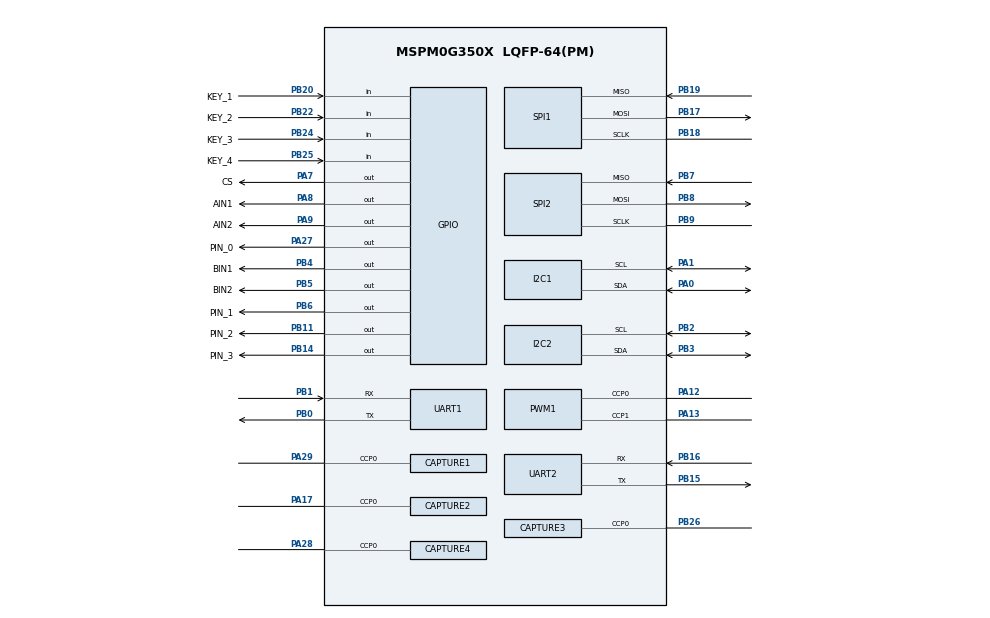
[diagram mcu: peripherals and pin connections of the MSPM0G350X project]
/**
 * @cliArgs --device "MSPM0G350X" --part "Default" --package "LQFP-64(PM)" --product "mspm0_sdk@2.10.00.04"
 * @versions {"tool":"1.26.2+4477"}
 */

/**
 * Import the modules used in this configuration.
 */
const CAPTURE  = scripting.addModule("/ti/driverlib/CAPTURE", {}, false);
const CAPTURE1 = CAPTURE.addInstance();
const CAPTURE2 = CAPTURE.addInstance();
const CAPTURE3 = CAPTURE.addInstance();
const CAPTURE4 = CAPTURE.addInstance();
const DMA      = scripting.addModule("/ti/driverlib/DMA");
const GPIO     = scripting.addModule("/ti/driverlib/GPIO", {}, false);
const GPIO1    = GPIO.addInstance();
const GPIO2    = GPIO.addInstance();
const GPIO3    = GPIO.addInstance();
const GPIO4    = GPIO.addInstance();
const GPIO5    = GPIO.addInstance();
const GPIO6    = GPIO.addInstance();
const GPIO7    = GPIO.addInstance();
const I2C      = scripting.addModule("/ti/driverlib/I2C", {}, false);
const I2C1     = I2C.addInstance();
const I2C2     = I2C.addInstance();
const PWM      = scripting.addModule("/ti/driverlib/PWM", {}, false);
const PWM1     = PWM.addInstance();
const SPI      = scripting.addModule("/ti/driverlib/SPI", {}, false);
const SPI1     = SPI.addInstance();
const SPI2     = SPI.addInstance();
const SYSCTL   = scripting.addModule("/ti/driverlib/SYSCTL");
const TIMER    = scripting.addModule("/ti/driverlib/TIMER", {}, false);
const TIMER1   = TIMER.addInstance();
const UART     = scripting.addModule("/ti/driverlib/UART", {}, false);
const UART1    = UART.addInstance();
const UART2    = UART.addInstance();
const UART3    = UART.addInstance();

/**
 * Write custom configuration values to the imported modules.
 */
const divider9       = system.clockTree["UDIV"];
divider9.divideValue = 2;

const mux4       = system.clockTree["EXHFMUX"];
mux4.inputSelect = "EXHFMUX_XTAL";

const mux8       = system.clockTree["HSCLKMUX"];
mux8.inputSelect = "HSCLKMUX_SYSPLL2X";

const mux12       = system.clockTree["SYSPLLMUX"];
mux12.inputSelect = "zSYSPLLMUX_HFCLK";

const pinFunction4        = system.clockTree["HFXT"];
pinFunction4.enable       = true;
pinFunction4.inputFreq    = 40;
pinFunction4.HFXTStartup  = 20;
pinFunction4.HFCLKMonitor = true;

CAPTURE1.$name                              = "E1A";
CAPTURE1.timerClkPrescale                   = 10;
CAPTURE1.interrupts                         = ["CC0_DN","CC0_UP","ZERO"];
CAPTURE1.captEdgeDetection                  = "EDGE";
CAPTURE1.timerPeriod                        = "20ms";
CAPTURE1.timerClkDiv                        = 8;
CAPTURE1.peripheral.$assign                 = "TIMG8";
CAPTURE1.peripheral.ccp0Pin.$assign         = "PA29";
CAPTURE1.ccp0PinConfig.$name                = "ti_driverlib_gpio_GPIOPinGeneric0";
CAPTURE1.ccp0PinConfig.hideOutputInversion  = scripting.forceWrite(false);
CAPTURE1.ccp0PinConfig.onlyInternalResistor = scripting.forceWrite(false);
CAPTURE1.ccp0PinConfig.passedPeripheralType = scripting.forceWrite("Digital");

const Board = scripting.addModule("/ti/driverlib/Board", {}, false);

CAPTURE2.$name                              = "E1B";
CAPTURE2.timerClkDiv                        = 8;
CAPTURE2.timerClkPrescale                   = 10;
CAPTURE2.interrupts                         = ["CC0_DN","CC0_UP","ZERO"];
CAPTURE2.captEdgeDetection                  = "EDGE";
CAPTURE2.timerPeriod                        = "20ms";
CAPTURE2.peripheral.$assign                 = "TIMA1";
CAPTURE2.peripheral.ccp0Pin.$assign         = "PA17";
CAPTURE2.ccp0PinConfig.$name                = "ti_driverlib_gpio_GPIOPinGeneric1";
CAPTURE2.ccp0PinConfig.hideOutputInversion  = scripting.forceWrite(false);
CAPTURE2.ccp0PinConfig.onlyInternalResistor = scripting.forceWrite(false);
CAPTURE2.ccp0PinConfig.passedPeripheralType = scripting.forceWrite("Digital");

CAPTURE3.$name                              = "E2A";
CAPTURE3.timerClkDiv                        = 8;
CAPTURE3.timerClkPrescale                   = 10;
CAPTURE3.interrupts                         = ["CC0_DN","CC0_UP","ZERO"];
CAPTURE3.captEdgeDetection                  = "EDGE";
CAPTURE3.timerPeriod                        = "20ms";
CAPTURE3.peripheral.$assign                 = "TIMG6";
CAPTURE3.peripheral.ccp0Pin.$assign         = "PB26";
CAPTURE3.ccp0PinConfig.$name                = "ti_driverlib_gpio_GPIOPinGeneric2";
CAPTURE3.ccp0PinConfig.hideOutputInversion  = scripting.forceWrite(false);
CAPTURE3.ccp0PinConfig.onlyInternalResistor = scripting.forceWrite(false);
CAPTURE3.ccp0PinConfig.passedPeripheralType = scripting.forceWrite("Digital");

CAPTURE4.$name                              = "E2B";
CAPTURE4.timerClkDiv                        = 8;
CAPTURE4.timerClkPrescale                   = 10;
CAPTURE4.interrupts                         = ["CC0_DN","CC0_UP","ZERO"];
CAPTURE4.captEdgeDetection                  = "EDGE";
CAPTURE4.timerPeriod                        = "20 ms";
CAPTURE4.peripheral.$assign                 = "TIMG7";
CAPTURE4.peripheral.ccp0Pin.$assign         = "PA28";
CAPTURE4.ccp0PinConfig.$name                = "ti_driverlib_gpio_GPIOPinGeneric3";
CAPTURE4.ccp0PinConfig.hideOutputInversion  = scripting.forceWrite(false);
CAPTURE4.ccp0PinConfig.onlyInternalResistor = scripting.forceWrite(false);
CAPTURE4.ccp0PinConfig.passedPeripheralType = scripting.forceWrite("Digital");

GPIO1.$name                         = "DC_Motor";
GPIO1.associatedPins.create(4);
GPIO1.associatedPins[0].$name       = "AIN1";
GPIO1.associatedPins[0].pin.$assign = "PA8";
GPIO1.associatedPins[1].$name       = "AIN2";
GPIO1.associatedPins[1].pin.$assign = "PA9";
GPIO1.associatedPins[2].$name       = "BIN1";
GPIO1.associatedPins[2].pin.$assign = "PB4";
GPIO1.associatedPins[3].$name       = "BIN2";
GPIO1.associatedPins[3].pin.$assign = "PB5";

GPIO2.$name                              = "KEY";
GPIO2.associatedPins.create(4);
GPIO2.associatedPins[0].$name            = "KEY_1";
GPIO2.associatedPins[0].direction        = "INPUT";
GPIO2.associatedPins[0].internalResistor = "PULL_UP";
GPIO2.associatedPins[0].pin.$assign      = "PB20";
GPIO2.associatedPins[1].$name            = "KEY_2";
GPIO2.associatedPins[1].direction        = "INPUT";
GPIO2.associatedPins[1].internalResistor = "PULL_UP";
GPIO2.associatedPins[1].pin.$assign      = "PB22";
GPIO2.associatedPins[2].$name            = "KEY_3";
GPIO2.associatedPins[2].direction        = "INPUT";
GPIO2.associatedPins[2].internalResistor = "PULL_UP";
GPIO2.associatedPins[2].pin.$assign      = "PB24";
GPIO2.associatedPins[3].$name            = "KEY_4";
GPIO2.associatedPins[3].direction        = "INPUT";
GPIO2.associatedPins[3].internalResistor = "PULL_UP";
GPIO2.associatedPins[3].pin.$assign      = "PB25";

GPIO3.$name                         = "ICM42688P";
GPIO3.port                          = "PORTA";
GPIO3.associatedPins[0].$name       = "CS";
GPIO3.associatedPins[0].pin.$assign = "PA7";

GPIO4.$name                         = "BUZZER";
GPIO4.associatedPins[0].$name       = "PIN_0";
GPIO4.associatedPins[0].pin.$assign = "PA27";

GPIO5.$name                         = "FLASH_CS";
GPIO5.associatedPins[0].$name       = "PIN_1";
GPIO5.associatedPins[0].pin.$assign = "PB6";

GPIO6.$name                         = "LED_RED";
GPIO6.associatedPins[0].$name       = "PIN_2";
GPIO6.associatedPins[0].pin.$assign = "PB11";

GPIO7.$name                         = "LED_GREEN";
GPIO7.associatedPins[0].$name       = "PIN_3";
GPIO7.associatedPins[0].pin.$assign = "PB14";

I2C1.$name                             = "I2C_OLED";
I2C1.advDigitalGlitchFilter            = "CLOCKS_1";
I2C1.enableDMAEvent1                   = false;
I2C1.enableDMAEvent2                   = false;
I2C1.basicEnableTarget                 = true;
I2C1.basicEnableController             = true;
I2C1.basicTargetSecAddressEnable       = true;
I2C1.basicControllerStandardBusSpeed   = "FastPlus";
I2C1.peripheral.$assign                = "I2C0";
I2C1.peripheral.sdaPin.$assign         = "PA0";
I2C1.peripheral.sclPin.$assign         = "PA1";
I2C1.sdaPinConfig.$name                = "ti_driverlib_gpio_GPIOPinGeneric4";
I2C1.sdaPinConfig.hideOutputInversion  = scripting.forceWrite(false);
I2C1.sdaPinConfig.onlyInternalResistor = scripting.forceWrite(false);
I2C1.sdaPinConfig.passedPeripheralType = scripting.forceWrite("Digital");
I2C1.sclPinConfig.$name                = "ti_driverlib_gpio_GPIOPinGeneric5";
I2C1.sclPinConfig.hideOutputInversion  = scripting.forceWrite(false);
I2C1.sclPinConfig.onlyInternalResistor = scripting.forceWrite(false);
I2C1.sclPinConfig.passedPeripheralType = scripting.forceWrite("Digital");

I2C2.$name                             = "I2C_GRAYSCALE";
I2C2.basicEnableController             = true;
I2C2.basicClockSourceDivider           = 4;
I2C2.peripheral.$assign                = "I2C1";
I2C2.peripheral.sdaPin.$assign         = "PB3";
I2C2.peripheral.sclPin.$assign         = "PB2";
I2C2.sdaPinConfig.hideOutputInversion  = scripting.forceWrite(false);
I2C2.sdaPinConfig.onlyInternalResistor = scripting.forceWrite(false);
I2C2.sdaPinConfig.passedPeripheralType = scripting.forceWrite("Digital");
I2C2.sdaPinConfig.$name                = "ti_driverlib_gpio_GPIOPinGeneric11";
I2C2.sclPinConfig.hideOutputInversion  = scripting.forceWrite(false);
I2C2.sclPinConfig.onlyInternalResistor = scripting.forceWrite(false);
I2C2.sclPinConfig.passedPeripheralType = scripting.forceWrite("Digital");
I2C2.sclPinConfig.$name                = "ti_driverlib_gpio_GPIOPinGeneric12";

PWM1.$name                              = "DC_Motor_PWM";
PWM1.clockDivider                       = 2;
PWM1.timerStartTimer                    = true;
PWM1.peripheral.$assign                 = "TIMG0";
PWM1.peripheral.ccp0Pin.$assign         = "PA12";
PWM1.peripheral.ccp1Pin.$assign         = "PA13";
PWM1.PWM_CHANNEL_0.$name                = "ti_driverlib_pwm_PWMTimerCC0";
PWM1.PWM_CHANNEL_0.invert               = true;
PWM1.PWM_CHANNEL_1.$name                = "ti_driverlib_pwm_PWMTimerCC1";
PWM1.PWM_CHANNEL_1.invert               = true;
PWM1.ccp0PinConfig.direction            = scripting.forceWrite("OUTPUT");
PWM1.ccp0PinConfig.hideOutputInversion  = scripting.forceWrite(false);
PWM1.ccp0PinConfig.onlyInternalResistor = scripting.forceWrite(false);
PWM1.ccp0PinConfig.passedPeripheralType = scripting.forceWrite("Digital");
PWM1.ccp0PinConfig.$name                = "ti_driverlib_gpio_GPIOPinGeneric6";
PWM1.ccp1PinConfig.direction            = scripting.forceWrite("OUTPUT");
PWM1.ccp1PinConfig.hideOutputInversion  = scripting.forceWrite(false);
PWM1.ccp1PinConfig.onlyInternalResistor = scripting.forceWrite(false);
PWM1.ccp1PinConfig.passedPeripheralType = scripting.forceWrite("Digital");
PWM1.ccp1PinConfig.$name                = "ti_driverlib_gpio_GPIOPinGeneric7";

SPI1.enableDMAEvent1                    = false;
SPI1.enableDMAEvent2                    = false;
SPI1.targetBitRate                      = 1000000;
SPI1.frameFormat                        = "MOTO3";
SPI1.chipSelect                         = [];
SPI1.$name                              = "SPI_ICM";
SPI1.sclkPinConfig.direction            = scripting.forceWrite("OUTPUT");
SPI1.sclkPinConfig.onlyInternalResistor = scripting.forceWrite(false);
SPI1.sclkPinConfig.passedPeripheralType = scripting.forceWrite("Digital");
SPI1.sclkPinConfig.$name                = "ti_driverlib_gpio_GPIOPinGeneric8";
SPI1.mosiPinConfig.direction            = scripting.forceWrite("OUTPUT");
SPI1.mosiPinConfig.hideOutputInversion  = scripting.forceWrite(false);
SPI1.mosiPinConfig.onlyInternalResistor = scripting.forceWrite(false);
SPI1.mosiPinConfig.passedPeripheralType = scripting.forceWrite("Digital");
SPI1.mosiPinConfig.$name                = "ti_driverlib_gpio_GPIOPinGeneric9";
SPI1.misoPinConfig.onlyInternalResistor = scripting.forceWrite(false);
SPI1.misoPinConfig.passedPeripheralType = scripting.forceWrite("Digital");
SPI1.misoPinConfig.$name                = "ti_driverlib_gpio_GPIOPinGeneric10";
SPI1.peripheral.$assign                 = "SPI0";
SPI1.peripheral.sclkPin.$assign         = "PB18";
SPI1.peripheral.mosiPin.$assign         = "PB17";
SPI1.peripheral.misoPin.$assign         = "PB19";

SPI2.$name                              = "SPI_FLASH";
SPI2.targetBitRate                      = 1000000;
SPI2.rxFifoThreshold                    = "DL_SPI_RX_FIFO_LEVEL_ONE_FRAME";
SPI2.txFifoThreshold                    = "DL_SPI_TX_FIFO_LEVEL_3_4_EMPTY";
SPI2.chipSelect                         = [];
SPI2.frameFormat                        = "MOTO3";
SPI2.sclkPinConfig.direction            = scripting.forceWrite("OUTPUT");
SPI2.sclkPinConfig.onlyInternalResistor = scripting.forceWrite(false);
SPI2.sclkPinConfig.passedPeripheralType = scripting.forceWrite("Digital");
SPI2.sclkPinConfig.$name                = "ti_driverlib_gpio_GPIOPinGeneric19";
SPI2.mosiPinConfig.direction            = scripting.forceWrite("OUTPUT");
SPI2.mosiPinConfig.hideOutputInversion  = scripting.forceWrite(false);
SPI2.mosiPinConfig.onlyInternalResistor = scripting.forceWrite(false);
SPI2.mosiPinConfig.passedPeripheralType = scripting.forceWrite("Digital");
SPI2.mosiPinConfig.$name                = "ti_driverlib_gpio_GPIOPinGeneric20";
SPI2.misoPinConfig.onlyInternalResistor = scripting.forceWrite(false);
SPI2.misoPinConfig.passedPeripheralType = scripting.forceWrite("Digital");
SPI2.misoPinConfig.$name                = "ti_driverlib_gpio_GPIOPinGeneric21";
SPI2.peripheral.sclkPin.$assign         = "PB9";
SPI2.peripheral.mosiPin.$assign         = "PB8";
SPI2.peripheral.misoPin.$assign         = "PB7";

SYSCTL.clockTreeEn       = true;
SYSCTL.validateClkStatus = true;

TIMER1.timerPeriod        = "1ms";
TIMER1.timerMode          = "PERIODIC";
TIMER1.timerClkPrescale   = 10;
TIMER1.timerClkDiv        = 8;
TIMER1.interrupts         = ["ZERO"];
TIMER1.$name              = "TIMER_FOR_1MS";
TIMER1.peripheral.$assign = "TIMA0";

UART1.enableFIFO                        = true;
UART1.rxFifoThreshold                   = "DL_UART_RX_FIFO_LEVEL_ONE_ENTRY";
UART1.enabledDMATXTriggers              = "DL_UART_DMA_INTERRUPT_TX";
UART1.enabledDMARXTriggers              = "DL_UART_DMA_INTERRUPT_RX";
UART1.txFifoThreshold                   = "DL_UART_TX_FIFO_LEVEL_EMPTY";
UART1.targetBaudRate                    = 38400;
UART1.$name                             = "UART_BLUETOOTH";
UART1.peripheral.$assign                = "UART0";
UART1.peripheral.rxPin.$assign          = "PB1";
UART1.peripheral.txPin.$assign          = "PB0";
UART1.txPinConfig.direction             = scripting.forceWrite("OUTPUT");
UART1.txPinConfig.hideOutputInversion   = scripting.forceWrite(false);
UART1.txPinConfig.onlyInternalResistor  = scripting.forceWrite(false);
UART1.txPinConfig.passedPeripheralType  = scripting.forceWrite("Digital");
UART1.txPinConfig.$name                 = "ti_driverlib_gpio_GPIOPinGeneric14";
UART1.rxPinConfig.hideOutputInversion   = scripting.forceWrite(false);
UART1.rxPinConfig.onlyInternalResistor  = scripting.forceWrite(false);
UART1.rxPinConfig.passedPeripheralType  = scripting.forceWrite("Digital");
UART1.rxPinConfig.$name                 = "ti_driverlib_gpio_GPIOPinGeneric15";
UART1.DMA_CHANNEL_TX.$name              = "DMA_CH1";
UART1.DMA_CHANNEL_TX.addressMode        = "b2f";
UART1.DMA_CHANNEL_TX.dstLength          = "BYTE";
UART1.DMA_CHANNEL_TX.srcLength          = "BYTE";
UART1.DMA_CHANNEL_TX.peripheral.$assign = "DMA_CH1";
UART1.DMA_CHANNEL_RX.$name              = "DMA_CH0";
UART1.DMA_CHANNEL_RX.addressMode        = "f2b";
UART1.DMA_CHANNEL_RX.dstLength          = "BYTE";
UART1.DMA_CHANNEL_RX.srcLength          = "BYTE";
UART1.DMA_CHANNEL_RX.peripheral.$assign = "DMA_CH0";

UART2.targetBaudRate                   = 115200;
UART2.enableFIFO                       = true;
UART2.rxFifoThreshold                  = "DL_UART_RX_FIFO_LEVEL_ONE_ENTRY";
UART2.txFifoThreshold                  = "DL_UART_TX_FIFO_LEVEL_EMPTY";
UART2.enabledDMARXTriggers             = "DL_UART_DMA_INTERRUPT_RX";
UART2.enabledDMATXTriggers             = "DL_UART_DMA_INTERRUPT_TX";
UART2.$name                            = "UART_STEPMOTOR";
UART2.peripheral.rxPin.$assign         = "PB16";
UART2.peripheral.txPin.$assign         = "PB15";
UART2.txPinConfig.direction            = scripting.forceWrite("OUTPUT");
UART2.txPinConfig.hideOutputInversion  = scripting.forceWrite(false);
UART2.txPinConfig.onlyInternalResistor = scripting.forceWrite(false);
UART2.txPinConfig.passedPeripheralType = scripting.forceWrite("Digital");
UART2.txPinConfig.$name                = "ti_driverlib_gpio_GPIOPinGeneric13";
UART2.rxPinConfig.hideOutputInversion  = scripting.forceWrite(false);
UART2.rxPinConfig.onlyInternalResistor = scripting.forceWrite(false);
UART2.rxPinConfig.passedPeripheralType = scripting.forceWrite("Digital");
UART2.rxPinConfig.$name                = "ti_driverlib_gpio_GPIOPinGeneric16";
UART2.DMA_CHANNEL_RX.$name             = "DMA_CH2";
UART2.DMA_CHANNEL_RX.srcLength         = "BYTE";
UART2.DMA_CHANNEL_RX.dstLength         = "BYTE";
UART2.DMA_CHANNEL_RX.addressMode       = "f2b";
UART2.DMA_CHANNEL_TX.$name             = "DMA_CH3";
UART2.DMA_CHANNEL_TX.addressMode       = "b2f";
UART2.DMA_CHANNEL_TX.srcLength         = "BYTE";
UART2.DMA_CHANNEL_TX.dstLength         = "BYTE";

UART3.targetBaudRate                   = 115200;
UART3.enableFIFO                       = true;
UART3.rxFifoThreshold                  = "DL_UART_RX_FIFO_LEVEL_ONE_ENTRY";
UART3.txFifoThreshold                  = "DL_UART_TX_FIFO_LEVEL_EMPTY";
UART3.enabledDMARXTriggers             = "DL_UART_DMA_INTERRUPT_RX";
UART3.enabledDMATXTriggers             = "DL_UART_DMA_INTERRUPT_TX";
UART3.$name                            = "UART_CAM";
UART3.txPinConfig.direction            = scripting.forceWrite("OUTPUT");
UART3.txPinConfig.hideOutputInversion  = scripting.forceWrite(false);
UART3.txPinConfig.onlyInternalResistor = scripting.forceWrite(false);
UART3.txPinConfig.passedPeripheralType = scripting.forceWrite("Digital");
UART3.txPinConfig.$name                = "ti_driverlib_gpio_GPIOPinGeneric17";
UART3.rxPinConfig.hideOutputInversion  = scripting.forceWrite(false);
UART3.rxPinConfig.onlyInternalResistor = scripting.forceWrite(false);
UART3.rxPinConfig.passedPeripheralType = scripting.forceWrite("Digital");
UART3.rxPinConfig.$name                = "ti_driverlib_gpio_GPIOPinGeneric18";
UART3.DMA_CHANNEL_RX.$name             = "DMA_CH4";
UART3.DMA_CHANNEL_RX.srcLength         = "BYTE";
UART3.DMA_CHANNEL_RX.dstLength         = "BYTE";
UART3.DMA_CHANNEL_RX.addressMode       = "f2b";
UART3.DMA_CHANNEL_TX.$name             = "DMA_CH5";
UART3.DMA_CHANNEL_TX.srcLength         = "BYTE";
UART3.DMA_CHANNEL_TX.dstLength         = "BYTE";
UART3.DMA_CHANNEL_TX.addressMode       = "b2f";

/**
 * Pinmux solution for unlocked pins/peripherals. This ensures that minor changes to the automatic solver in a future
 * version of the tool will not impact the pinmux you originally saw.  These lines can be completely deleted in order to
 * re-solve from scratch.
 */
pinFunction4.peripheral.$suggestSolution           = "SYSCTL";
pinFunction4.peripheral.hfxInPin.$suggestSolution  = "PA5";
pinFunction4.peripheral.hfxOutPin.$suggestSolution = "PA6";
Board.peripheral.$suggestSolution                  = "DEBUGSS";
Board.peripheral.swclkPin.$suggestSolution         = "PA20";
Board.peripheral.swdioPin.$suggestSolution         = "PA19";
SPI2.peripheral.$suggestSolution                   = "SPI1";
UART2.peripheral.$suggestSolution                  = "UART2";
UART2.DMA_CHANNEL_RX.peripheral.$suggestSolution   = "DMA_CH5";
UART2.DMA_CHANNEL_TX.peripheral.$suggestSolution   = "DMA_CH4";
UART3.peripheral.$suggestSolution                  = "UART3";
UART3.peripheral.rxPin.$suggestSolution            = "PA25";
UART3.peripheral.txPin.$suggestSolution            = "PA14";
UART3.DMA_CHANNEL_RX.peripheral.$suggestSolution   = "DMA_CH3";
UART3.DMA_CHANNEL_TX.peripheral.$suggestSolution   = "DMA_CH2";
